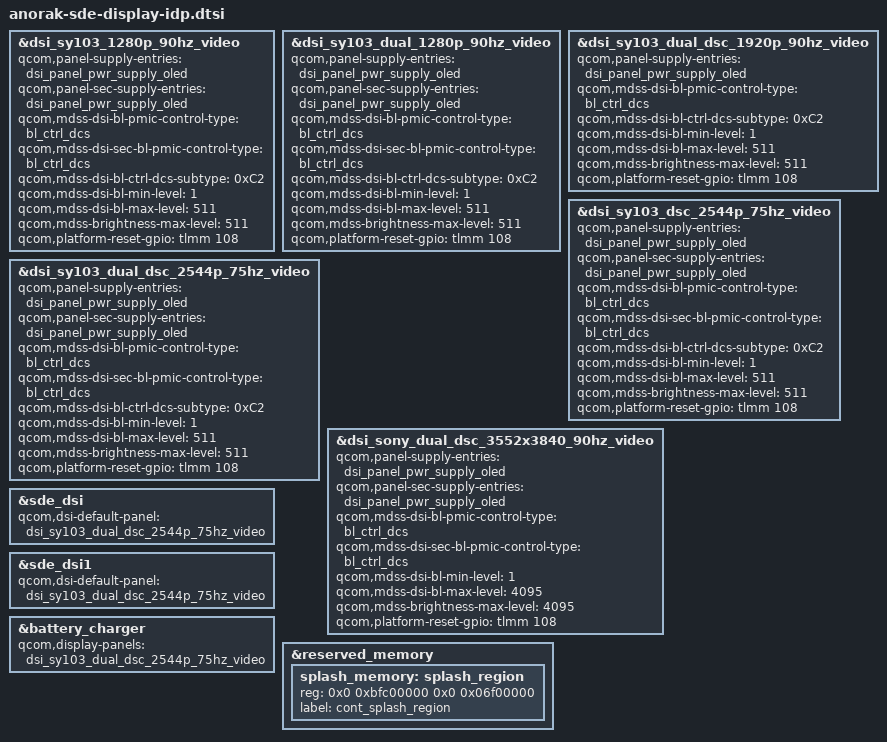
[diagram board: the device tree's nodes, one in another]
#include "anorak-sde-display.dtsi"

&dsi_sy103_1280p_90hz_video {
	qcom,panel-supply-entries = <&dsi_panel_pwr_supply_oled>;
	qcom,panel-sec-supply-entries = <&dsi_panel_pwr_supply_oled>;
	qcom,mdss-dsi-bl-pmic-control-type = "bl_ctrl_dcs";
	qcom,mdss-dsi-sec-bl-pmic-control-type = "bl_ctrl_dcs";
	qcom,mdss-dsi-bl-ctrl-dcs-subtype = <0xC2>;
	qcom,mdss-dsi-bl-min-level = <1>;
	qcom,mdss-dsi-bl-max-level = <511>;
	qcom,mdss-brightness-max-level = <511>;
	qcom,platform-reset-gpio = <&tlmm 108 0>;
};

&dsi_sy103_dual_1280p_90hz_video {
	qcom,panel-supply-entries = <&dsi_panel_pwr_supply_oled>;
	qcom,panel-sec-supply-entries = <&dsi_panel_pwr_supply_oled>;
	qcom,mdss-dsi-bl-pmic-control-type = "bl_ctrl_dcs";
	qcom,mdss-dsi-sec-bl-pmic-control-type = "bl_ctrl_dcs";
	qcom,mdss-dsi-bl-ctrl-dcs-subtype = <0xC2>;
	qcom,mdss-dsi-bl-min-level = <1>;
	qcom,mdss-dsi-bl-max-level = <511>;
	qcom,mdss-brightness-max-level = <511>;
	qcom,platform-reset-gpio = <&tlmm 108 0>;
};

&dsi_sy103_dual_dsc_1920p_90hz_video {
	qcom,panel-supply-entries = <&dsi_panel_pwr_supply_oled>;
	qcom,mdss-dsi-bl-pmic-control-type = "bl_ctrl_dcs";
	qcom,mdss-dsi-bl-ctrl-dcs-subtype = <0xC2>;
	qcom,mdss-dsi-bl-min-level = <1>;
	qcom,mdss-dsi-bl-max-level = <511>;
	qcom,mdss-brightness-max-level = <511>;
	qcom,platform-reset-gpio = <&tlmm 108 0>;
};

&dsi_sy103_dsc_2544p_75hz_video {
	qcom,panel-supply-entries = <&dsi_panel_pwr_supply_oled>;
	qcom,panel-sec-supply-entries = <&dsi_panel_pwr_supply_oled>;
	qcom,mdss-dsi-bl-pmic-control-type = "bl_ctrl_dcs";
	qcom,mdss-dsi-sec-bl-pmic-control-type = "bl_ctrl_dcs";
	qcom,mdss-dsi-bl-ctrl-dcs-subtype = <0xC2>;
	qcom,mdss-dsi-bl-min-level = <1>;
	qcom,mdss-dsi-bl-max-level = <511>;
	qcom,mdss-brightness-max-level = <511>;
	qcom,platform-reset-gpio = <&tlmm 108 0>;
};

&dsi_sy103_dual_dsc_2544p_75hz_video {
        qcom,panel-supply-entries = <&dsi_panel_pwr_supply_oled>;
	qcom,panel-sec-supply-entries = <&dsi_panel_pwr_supply_oled>;
        qcom,mdss-dsi-bl-pmic-control-type = "bl_ctrl_dcs";
	qcom,mdss-dsi-sec-bl-pmic-control-type = "bl_ctrl_dcs";
	qcom,mdss-dsi-bl-ctrl-dcs-subtype = <0xC2>;
        qcom,mdss-dsi-bl-min-level = <1>;
        qcom,mdss-dsi-bl-max-level = <511>;
        qcom,mdss-brightness-max-level = <511>;
	qcom,platform-reset-gpio = <&tlmm 108 0>;
};

&dsi_sony_dual_dsc_3552x3840_90hz_video {
	qcom,panel-supply-entries = <&dsi_panel_pwr_supply_oled>;
	qcom,panel-sec-supply-entries = <&dsi_panel_pwr_supply_oled>;
	qcom,mdss-dsi-bl-pmic-control-type = "bl_ctrl_dcs";
	qcom,mdss-dsi-sec-bl-pmic-control-type = "bl_ctrl_dcs";
	qcom,mdss-dsi-bl-min-level = <1>;
	qcom,mdss-dsi-bl-max-level = <4095>;
	qcom,mdss-brightness-max-level = <4095>;
	qcom,platform-reset-gpio = <&tlmm 108 0>;
};

&sde_dsi {
	qcom,dsi-default-panel = <&dsi_sy103_dual_dsc_2544p_75hz_video>;
};

&sde_dsi1 {
	qcom,dsi-default-panel = <&dsi_sy103_dual_dsc_2544p_75hz_video>;
};

&battery_charger {
	qcom,display-panels = <&dsi_sy103_dual_dsc_2544p_75hz_video>;
};

&reserved_memory {
	splash_memory: splash_region {
		reg = <0x0 0xbfc00000 0x0 0x06f00000>;
		label = "cont_splash_region";
	};
};
